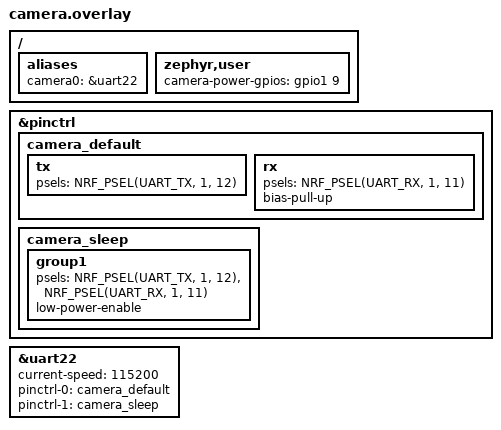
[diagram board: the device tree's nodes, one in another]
#include "carrier.overlay"
/ {
    aliases {
        /delete-property/ gps0;
        camera0 = &uart22;
    };
    zephyr,user {
        /delete-property/ gps-wake-gpios;
        camera-power-gpios = <&gpio1 9 GPIO_ACTIVE_HIGH>;
    };
};
/* Match the actual diagnostic code in offgrid-tracker commit 39820d3.
 * Camera RXD <- MCU P1.12; camera TXD -> MCU P1.11. GPS must be unplugged. */
&pinctrl {
    camera_default: camera_default {
        tx { psels = <NRF_PSEL(UART_TX, 1, 12)>; };
        rx { psels = <NRF_PSEL(UART_RX, 1, 11)>; bias-pull-up; };
    };
    camera_sleep: camera_sleep {
        group1 {
            psels = <NRF_PSEL(UART_TX, 1, 12)>, <NRF_PSEL(UART_RX, 1, 11)>;
            low-power-enable;
        };
    };
};
&uart22 {
    current-speed = <115200>;
    pinctrl-0 = <&camera_default>;
    pinctrl-1 = <&camera_sleep>;
    pinctrl-names = "default", "sleep";
};
